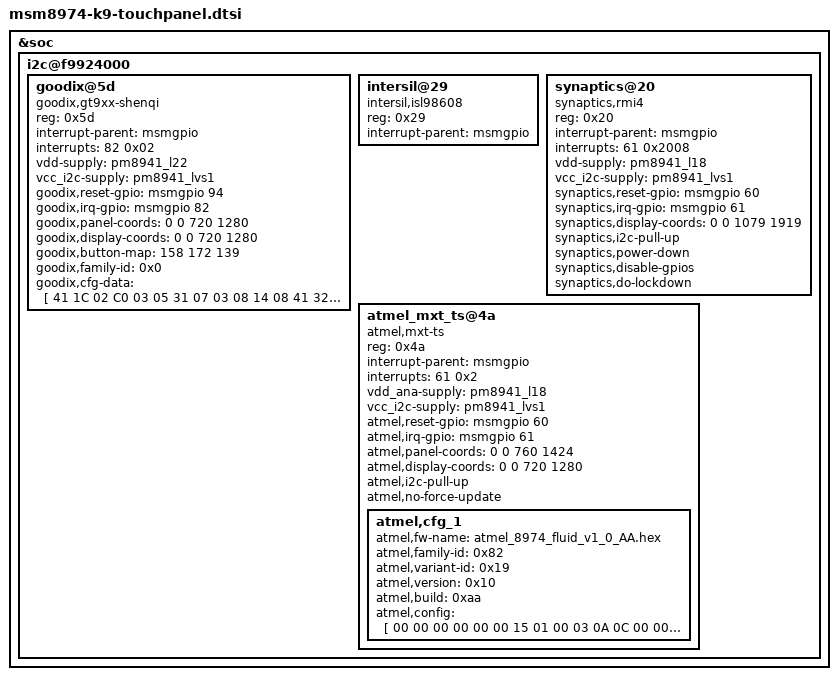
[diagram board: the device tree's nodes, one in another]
/*
 * Copyright (c) 2012-2013, The Linux Foundation. All rights reserved.
 *
 * This program is free software; you can redistribute it and/or modify
 * it under the terms of the GNU General Public License version 2 and
 * only version 2 as published by the Free Software Foundation.
 *
 * This program is distributed in the hope that it will be useful,
 * but WITHOUT ANY WARRANTY; without even the implied warranty of
 * MERCHANTABILITY or FITNESS FOR A PARTICULAR PURPOSE.  See the
 * GNU General Public License for more details.
 */

&soc {
	i2c@f9924000 {
		goodix@5d {
			compatible = "goodix,gt9xx-shenqi";
			reg = <0x5d>;
			interrupt-parent = <&msmgpio>;
			interrupts = <82 0x02>;
			vdd-supply = <&pm8941_l22>;
			vcc_i2c-supply = <&pm8941_lvs1>;
			/* pins used by touchscreen */
			//pinctrl-names = "pmx_ts_active","pmx_ts_suspend";
			//pinctrl-0 = <&ts_int_active &ts_reset_active>;
			//pinctrl-1 = <&ts_int_suspend &ts_reset_suspend>;
			goodix,reset-gpio = <&msmgpio 94 0x0>;
			goodix,irq-gpio = <&msmgpio 82 0x0>;
			//goodix,ldo-en-gpio = <&msmgpio 15 0x00>;
			goodix,panel-coords = <0 0 720 1280>;
			goodix,display-coords = <0 0 720 1280>;
			goodix,button-map= <158 172 139>;
			goodix,family-id = <0x0>;
			goodix,cfg-data = [
				41 1C 02 C0 03 05 31 07 03 08
				14 08 41 32 03 04 00 00 00 00
				00 00 00 18 1A 1E 14 8B 2B 0C
				1C 1E 8C 20 00 00 00 9A 03 2D
				00 00 00 00 00 00 00 00 00 22
				00 4B FA 94 85 02 05 00 00 E5
				1B 1A ED 1C 1C 3C 1F 1E 3C 1F
				24 08 27 1F 00 00 10 38 58 00
				67 60 45 FF FF 07 00 00 00 00
				00 01 06 14 0C 16 E8 03 02 00
				00 03 28 28 E5 00 23 23 00 00
				00 00 02 04 06 08 0A 0C 0E 10
				12 14 16 18 FF FF FF FF FF FF
				FF FF FF FF FF FF FF FF FF FF
				FF FF 00 02 04 06 08 0A 0C 0F
				10 12 13 16 18 1C 1D 1E 1F 20
				21 22 24 26 FF FF FF FF FF FF
				FF FF FF FF FF FF FF FF FF FF
				FF FF FF FF 90 01];
		};

		intersil@29 {
			compatible = "intersil,isl98608";
			reg = <0x29>;
			interrupt-parent = <&msmgpio>;
		};

		synaptics@20 {
			compatible = "synaptics,rmi4";
			reg = <0x20>;
			interrupt-parent = <&msmgpio>;
			interrupts = <61 0x2008>;
			vdd-supply = <&pm8941_l18>;
			vcc_i2c-supply = <&pm8941_lvs1>;
			synaptics,reset-gpio = <&msmgpio 60 0x00>;
			synaptics,irq-gpio = <&msmgpio 61 0x2008>;
			synaptics,display-coords = <0 0 1079 1919>;
			synaptics,i2c-pull-up;
			synaptics,power-down;
			synaptics,disable-gpios;
			synaptics,do-lockdown;
		};

		atmel_mxt_ts@4a {
			compatible = "atmel,mxt-ts";
			reg = <0x4a>;
			interrupt-parent = <&msmgpio>;
			interrupts = <61 0x2>;
			vdd_ana-supply = <&pm8941_l18>;
			vcc_i2c-supply = <&pm8941_lvs1>;
			atmel,reset-gpio = <&msmgpio 60 0x00>;
			atmel,irq-gpio = <&msmgpio 61 0x00>;
			atmel,panel-coords = <0  0 760 1424>;
			atmel,display-coords = <0 0 720 1280>;
			atmel,i2c-pull-up;
			atmel,no-force-update;
			atmel,cfg_1 {
				atmel,fw-name = "atmel_8974_fluid_v1_0_AA.hex";
				atmel,family-id = <0x82>;
				atmel,variant-id = <0x19>;
				atmel,version = <0x10>;
				atmel,build = <0xaa>;
				atmel,config = [
					/* Object 6, Instance = 0 */
					00 00 00 00 00 00
					/* Object 38, Instance = 0 */
					15 01 00 03 0A 0C 00 00
					/* Object 7, Instance = 0 */
					20 08 32 03
					/* Object 8, Instance = 0 */
					0F 00 0A 0A 00 00 0A 0A 00 00
					/* Object 9, Instance = 0 */
					83 00 00 18 0E 00 70 46 02 01
					00 0A 03 31 04 05 0A 0A 90 05
					F8 02 05 F1 F1 0F 00 00 08 2D
					12 06 00 00 00 01
					/* Object 15, Instance = 0 */
					00 00 00 00 00 00 00 00 00 00
					00
					/* Object 18, Instance = 0 */
					00 00
					/* Object 19, Instance = 0 */
					00 00 00 00 00 00
					/* Object 23, Instance = 0 */
					00 00 00 00 00 00 00 00 00 00
					00 00 00 00 00
					/* Object 25, Instance = 0 */
					00 00 00 00 00 00 00 00 00 00
					00 00 00 00 00
					/* Object 40, Instance = 0 */
					00 00 00 00 00
					/* Object 42, Instance = 0 */
					33 1E 19 10 80 00 00 00 FF 00
					/* Object 46, Instance = 0 */
					00 00 10 10 00 00 03 00 00 01
					/* Object 47, Instance = 0 */
					08 0A 28 0A 02 0A 00 8C 00 20
					00 00 00
					/* Object 55, Instance = 0 */
					00 00 00 00 00 00
					/* Object 56, Instance = 0 */
					00 00 00 18 05 05 05 05 05 05
					05 05 05 05 05 05 05 05 05 05
					05 05 05 05 05 05 05 05 00 00
					00 00 00 00 00 00 00 00 00 00
					00 00
					/* Object 57, Instance = 0 */
					00 00 00
					/* Object 61, Instance = 0 */
					00 00 00 00 00
					/* Object 62, Instance = 0 */
					01 2A 00 16 00 00 00 00 0B 01
					02 03 04 08 00 00 08 10 18 05
					00 0A 05 05 50 14 19 34 1A 7F
					00 00 00 00 00 00 00 00 00 30
					05 02 00 01 00 05 00 00 00 00
					00 00 00 00
					];
			};
		};
	};
};
